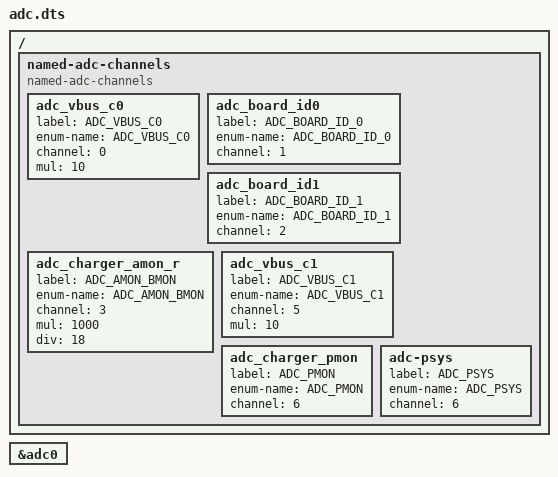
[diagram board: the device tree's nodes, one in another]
/* Copyright 2021 The Chromium OS Authors. All rights reserved.
 * Use of this source code is governed by a BSD-style license that can be
 * found in the LICENSE file.
 */

/ {
	named-adc-channels {
		compatible = "named-adc-channels";

		adc_vbus_c0 {
			label = "ADC_VBUS_C0";
			enum-name = "ADC_VBUS_C0";
			channel = <0>;
			mul = <10>;
		};
		adc_board_id0 {
			label = "ADC_BOARD_ID_0";
			enum-name = "ADC_BOARD_ID_0";
			channel = <1>;
		};
		adc_board_id1 {
			label = "ADC_BOARD_ID_1";
			enum-name = "ADC_BOARD_ID_1";
			channel = <2>;
		};
		adc_charger_amon_r {
			label = "ADC_AMON_BMON";
			enum-name = "ADC_AMON_BMON";
			channel = <3>;
			mul = <1000>;
			div = <18>;
		};
		adc_vbus_c1 {
			label = "ADC_VBUS_C1";
			enum-name = "ADC_VBUS_C1";
			channel = <5>;
			mul = <10>;
		};
		adc_charger_pmon {
			label = "ADC_PMON";
			enum-name = "ADC_PMON";
			channel = <6>;
		};
		adc-psys {
			label = "ADC_PSYS";
			enum-name = "ADC_PSYS";
			channel = <6>;
		};
	};
};

&adc0 {
	status = "okay";
};
